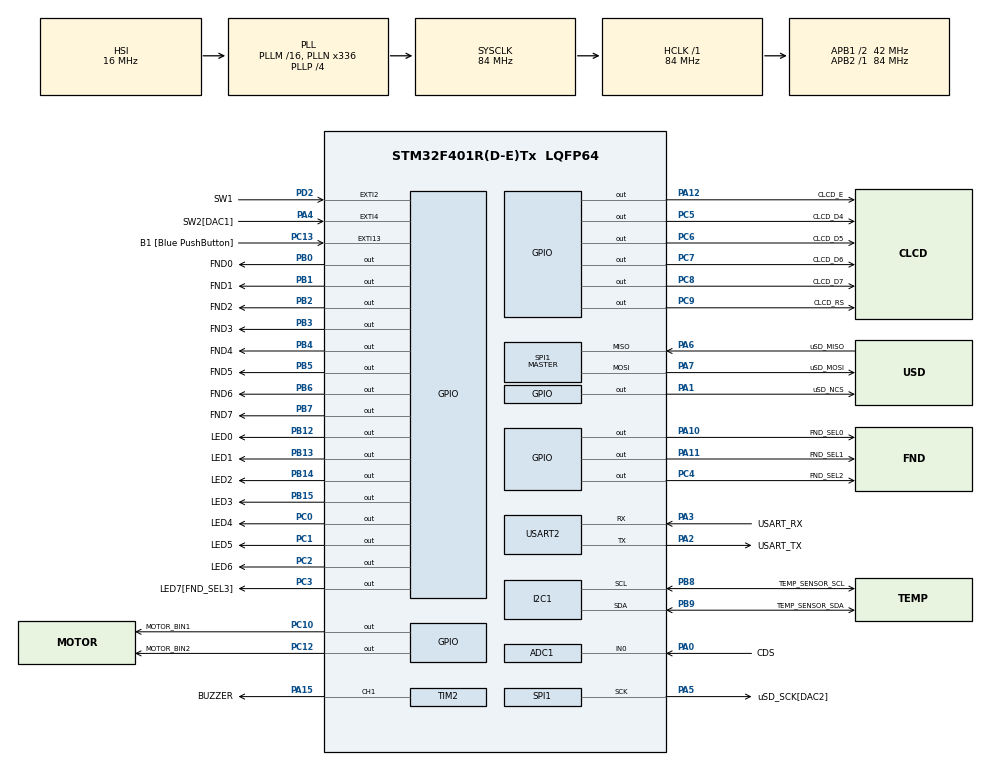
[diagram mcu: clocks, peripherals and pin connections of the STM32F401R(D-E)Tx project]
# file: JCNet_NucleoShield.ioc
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ADC1.Channel-0\#ChannelRegularConversion=ADC_CHANNEL_0
ADC1.Channel-1\#ChannelRegularConversion=ADC_CHANNEL_TEMPSENSOR
ADC1.ClockPrescaler=ADC_CLOCK_SYNC_PCLK_DIV4
ADC1.DMAContinuousRequests=ENABLE
ADC1.EOCSelection=ADC_EOC_SINGLE_CONV
ADC1.NbrOfConversion=2
ADC1.NbrOfConversionFlag=1
ADC1.Rank-0\#ChannelRegularConversion=1
ADC1.Rank-1\#ChannelRegularConversion=2
ADC1.SamplingTime-0\#ChannelRegularConversion=ADC_SAMPLETIME_480CYCLES
ADC1.SamplingTime-1\#ChannelRegularConversion=ADC_SAMPLETIME_480CYCLES
ADC1.ScanConvMode=ENABLE
ADC1.master=1
Dma.ADC1.0.Direction=DMA_PERIPH_TO_MEMORY
Dma.ADC1.0.FIFOMode=DMA_FIFOMODE_DISABLE
Dma.ADC1.0.Instance=DMA2_Stream0
Dma.ADC1.0.MemDataAlignment=DMA_MDATAALIGN_HALFWORD
Dma.ADC1.0.MemInc=DMA_MINC_ENABLE
Dma.ADC1.0.Mode=DMA_CIRCULAR
Dma.ADC1.0.PeriphDataAlignment=DMA_PDATAALIGN_HALFWORD
Dma.ADC1.0.PeriphInc=DMA_PINC_DISABLE
Dma.ADC1.0.Priority=DMA_PRIORITY_LOW
Dma.Request0=ADC1
Mcu.Family=STM32F4
Mcu.Name=STM32F401R(D-E)Tx
Mcu.Package=LQFP64
NVIC.ADC_IRQn=true\:0\:0\:false\:false\:true\:true\:true
NVIC.DMA2_Stream0_IRQn=true\:0\:0\:false\:false\:true\:false\:true
NVIC.EXTI2_IRQn=true\:0\:0\:true\:false\:true\:true\:true
NVIC.EXTI4_IRQn=true\:0\:0\:true\:false\:true\:true\:true
NVIC.PriorityGroup=NVIC_PRIORITYGROUP_4
NVIC.TIM2_IRQn=true\:0\:0\:false\:false\:true\:true\:true
PA0-WKUP.GPIO_Label=CDS
PA0-WKUP.Signal=ADCx_IN0
PA1.GPIO_Label=uSD_NCS
PA1.Signal=GPIO_Output
PA10.GPIO_Label=FND_SEL0
PA10.Signal=GPIO_Output
PA11.GPIO_Label=FND_SEL1
PA11.Signal=GPIO_Output
PA12.GPIO_Label=CLCD_E
PA12.GPIO_ModeDefaultOutputPP=GPIO_MODE_OUTPUT_OD
PA12.Signal=GPIO_Output
PA13.GPIO_Label=TMS
PA13.Mode=Serial_Wire
PA13.Signal=SYS_JTMS-SWDIO
PA14.GPIO_Label=TCK
PA14.Mode=Serial_Wire
PA14.Signal=SYS_JTCK-SWCLK
PA15.GPIO_Label=BUZZER
PA15.Signal=S_TIM2_CH1_ETR
PA2.GPIO_Label=USART_TX
PA2.GPIO_Mode=GPIO_MODE_AF_PP
PA2.GPIO_PuPd=GPIO_NOPULL
PA2.GPIO_Speed=GPIO_SPEED_FREQ_LOW
PA2.Mode=Asynchronous
PA2.Signal=USART2_TX
PA3.GPIO_Label=USART_RX
PA3.GPIO_Mode=GPIO_MODE_AF_PP
PA3.GPIO_PuPd=GPIO_NOPULL
PA3.GPIO_Speed=GPIO_SPEED_FREQ_LOW
PA3.Mode=Asynchronous
PA3.Signal=USART2_RX
PA4.GPIO_Label=SW2[DAC1]
PA4.GPIO_ModeDefaultEXTI=GPIO_MODE_IT_FALLING
PA4.Signal=GPXTI4
PA5.GPIO_Label=uSD_SCK[DAC2]
PA5.Mode=Full_Duplex_Master
PA5.Signal=SPI1_SCK
PA6.GPIO_Label=uSD_MISO
PA6.Mode=Full_Duplex_Master
PA6.Signal=SPI1_MISO
PA7.GPIO_Label=uSD_MOSI
PA7.Mode=Full_Duplex_Master
PA7.Signal=SPI1_MOSI
PA8.GPIO_Label=MOTOR_CH1
PA8.Signal=S_TIM1_CH1
PA9.GPIO_Label=MOTOR_CH2
PA9.Signal=S_TIM1_CH2
PB0.GPIO_Label=FND0
PB0.Signal=GPIO_Output
PB1.GPIO_Label=FND1
PB1.Signal=GPIO_Output
PB12.GPIO_Label=LED0
PB12.Signal=GPIO_Output
PB13.GPIO_Label=LED1
PB13.Signal=GPIO_Output
PB14.GPIO_Label=LED2
PB14.Signal=GPIO_Output
PB15.GPIO_Label=LED3
PB15.Signal=GPIO_Output
PB2.GPIO_Label=FND2
PB2.Signal=GPIO_Output
PB3.GPIO_Label=FND3
PB3.Signal=GPIO_Output
PB4.GPIO_Label=FND4
PB4.Signal=GPIO_Output
PB5.GPIO_Label=FND5
PB5.Signal=GPIO_Output
PB6.GPIO_Label=FND6
PB6.Signal=GPIO_Output
PB7.GPIO_Label=FND7
PB7.Signal=GPIO_Output
PB8.GPIO_Label=TEMP_SENSOR_SCL
PB8.Mode=I2C
PB8.Signal=I2C1_SCL
PB9.GPIO_Label=TEMP_SENSOR_SDA
PB9.Mode=I2C
PB9.Signal=I2C1_SDA
PC0.GPIO_Label=LED4
PC0.Signal=GPIO_Output
PC1.GPIO_Label=LED5
PC1.Signal=GPIO_Output
PC10.GPIO_Label=MOTOR_BIN1
PC10.Signal=GPIO_Output
PC12.GPIO_Label=MOTOR_BIN2
PC12.Signal=GPIO_Output
PC13-ANTI_TAMP.GPIO_Label=B1 [Blue PushButton]
PC13-ANTI_TAMP.GPIO_ModeDefaultEXTI=GPIO_MODE_IT_FALLING
PC13-ANTI_TAMP.GPIO_PuPd=GPIO_NOPULL
PC13-ANTI_TAMP.Signal=GPXTI13
PC14-OSC32_IN.Mode=LSE-External-Oscillator
PC14-OSC32_IN.Signal=RCC_OSC32_IN
PC15-OSC32_OUT.Mode=LSE-External-Oscillator
PC15-OSC32_OUT.Signal=RCC_OSC32_OUT
PC2.GPIO_Label=LED6
PC2.Signal=GPIO_Output
PC3.GPIO_Label=LED7[FND_SEL3]
PC3.Signal=GPIO_Output
PC4.GPIO_Label=FND_SEL2
PC4.Signal=GPIO_Output
PC5.GPIO_Label=CLCD_D4
PC5.GPIO_ModeDefaultOutputPP=GPIO_MODE_OUTPUT_OD
PC5.Signal=GPIO_Output
PC6.GPIO_Label=CLCD_D5
PC6.GPIO_ModeDefaultOutputPP=GPIO_MODE_OUTPUT_OD
PC6.Signal=GPIO_Output
PC7.GPIO_Label=CLCD_D6
PC7.GPIO_ModeDefaultOutputPP=GPIO_MODE_OUTPUT_OD
PC7.Signal=GPIO_Output
PC8.GPIO_Label=CLCD_D7
PC8.GPIO_ModeDefaultOutputPP=GPIO_MODE_OUTPUT_OD
PC8.Signal=GPIO_Output
PC9.GPIO_Label=CLCD_RS
PC9.GPIO_ModeDefaultOutputPP=GPIO_MODE_OUTPUT_OD
PC9.Signal=GPIO_Output
PD2.GPIO_Label=SW1
PD2.GPIO_ModeDefaultEXTI=GPIO_MODE_IT_FALLING
PD2.Signal=GPXTI2
PH0\ -\ OSC_IN.Mode=HSE-External-Clock-Source
PH0\ -\ OSC_IN.Signal=RCC_OSC_IN
PH1\ -\ OSC_OUT.Mode=HSE-External-Clock-Source
PH1\ -\ OSC_OUT.Signal=RCC_OSC_OUT
ProjectManager.HeapSize=0x200
ProjectManager.StackSize=0x400
ProjectManager.TargetToolchain=STM32CubeIDE
RCC.48MHZClocksFreq_Value=48000000
RCC.AHBFreq_Value=84000000
RCC.APB1CLKDivider=RCC_HCLK_DIV2
RCC.APB1Freq_Value=42000000
RCC.APB1TimFreq_Value=84000000
RCC.APB2Freq_Value=84000000
RCC.APB2TimFreq_Value=84000000
RCC.CortexFreq_Value=84000000
RCC.HCLKFreq_Value=84000000
RCC.HSE_VALUE=8000000
RCC.HSI_VALUE=16000000
RCC.PLLN=336
RCC.PLLP=RCC_PLLP_DIV4
RCC.PLLQ=7
RCC.SYSCLKFreq_VALUE=84000000
RCC.SYSCLKSource=RCC_SYSCLKSOURCE_PLLCLK
RCC.VCOOutputFreq_Value=336000000
SH.ADCx_IN0.0=ADC1_IN0,IN0
SH.S_TIM1_CH1.0=TIM1_CH1
SH.S_TIM1_CH2.0=TIM1_CH2
SH.S_TIM2_CH1_ETR.0=TIM2_CH1,PWM Generation1 CH1
SPI1.Direction=SPI_DIRECTION_2LINES
SPI1.Mode=SPI_MODE_MASTER
SPI1.VirtualType=VM_MASTER
TIM2.Channel-PWM\ Generation1\ CH1=TIM_CHANNEL_1
TIM2.Period=1000-1
TIM2.Prescaler=84-1
TIM2.Pulse-PWM\ Generation1\ CH1=500
USART2.VirtualMode=VM_ASYNC
VP_ADC1_TempSens_Input.Mode=IN-TempSens
board=NUCLEO-F401RE

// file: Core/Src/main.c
/* USER CODE BEGIN Header */
/**
  ******************************************************************************
  * @file           : main.c
  * @brief          : Main program body
  ******************************************************************************
  * @attention
  *
  * <h2><center>&copy; Copyright (c) 2020 STMicroelectronics.
  * All rights reserved.</center></h2>
  *
  * This software component is licensed by ST under BSD 3-Clause license,
  * the "License"; You may not use this file except in compliance with the
  * License. You may obtain a copy of the License at:
  *                        opensource.org/licenses/BSD-3-Clause
  *
  ******************************************************************************
  */
/* USER CODE END Header */

#include "main.h"

ADC_HandleTypeDef hadc1;
DMA_HandleTypeDef hdma_adc1;

I2C_HandleTypeDef hi2c1;

SPI_HandleTypeDef hspi1;

TIM_HandleTypeDef htim2;

UART_HandleTypeDef huart2;

void SystemClock_Config(void);
static void MX_GPIO_Init(void);
static void MX_DMA_Init(void);
static void MX_USART2_UART_Init(void);
static void MX_ADC1_Init(void);
static void MX_I2C1_Init(void);
static void MX_SPI1_Init(void);
static void MX_TIM2_Init(void);

int main(void)
{

  /* MCU Configuration--------------------------------------------------------*/

  /* Reset of all peripherals, Initializes the Flash interface and the Systick. */
  HAL_Init();

  /* Configure the system clock */
  SystemClock_Config();

  /* Initialize all configured peripherals */
  MX_GPIO_Init();
  MX_DMA_Init();
  MX_USART2_UART_Init();
  MX_ADC1_Init();
  MX_I2C1_Init();
  MX_SPI1_Init();
  MX_TIM2_Init();

  /* Infinite loop */
  /* USER CODE BEGIN WHILE */
  while (1)
  {
	  HAL_GPIO_TogglePin(LED0_GPIO_Port, LED0_Pin);
	  HAL_Delay(100);
    /* USER CODE END WHILE */

  }
}

void SystemClock_Config(void)
{
  RCC_OscInitTypeDef RCC_OscInitStruct = {0};
  RCC_ClkInitTypeDef RCC_ClkInitStruct = {0};

  /** Configure the main internal regulator output voltage
  */
  __HAL_RCC_PWR_CLK_ENABLE();
  __HAL_PWR_VOLTAGESCALING_CONFIG(PWR_REGULATOR_VOLTAGE_SCALE2);
  /** Initializes the CPU, AHB and APB busses clocks
  */
  RCC_OscInitStruct.OscillatorType = RCC_OSCILLATORTYPE_HSI;
  RCC_OscInitStruct.HSIState = RCC_HSI_ON;
  RCC_OscInitStruct.HSICalibrationValue = RCC_HSICALIBRATION_DEFAULT;
  RCC_OscInitStruct.PLL.PLLState = RCC_PLL_ON;
  RCC_OscInitStruct.PLL.PLLSource = RCC_PLLSOURCE_HSI;
  RCC_OscInitStruct.PLL.PLLM = 16;
  RCC_OscInitStruct.PLL.PLLN = 336;
  RCC_OscInitStruct.PLL.PLLP = RCC_PLLP_DIV4;
  RCC_OscInitStruct.PLL.PLLQ = 7;
  if (HAL_RCC_OscConfig(&RCC_OscInitStruct) != HAL_OK)
  {
    Error_Handler();
  }
  /** Initializes the CPU, AHB and APB busses clocks
  */
  RCC_ClkInitStruct.ClockType = RCC_CLOCKTYPE_HCLK|RCC_CLOCKTYPE_SYSCLK
                              |RCC_CLOCKTYPE_PCLK1|RCC_CLOCKTYPE_PCLK2;
  RCC_ClkInitStruct.SYSCLKSource = RCC_SYSCLKSOURCE_PLLCLK;
  RCC_ClkInitStruct.AHBCLKDivider = RCC_SYSCLK_DIV1;
  RCC_ClkInitStruct.APB1CLKDivider = RCC_HCLK_DIV2;
  RCC_ClkInitStruct.APB2CLKDivider = RCC_HCLK_DIV1;

  if (HAL_RCC_ClockConfig(&RCC_ClkInitStruct, FLASH_LATENCY_2) != HAL_OK)
  {
    Error_Handler();
  }
}

static void MX_ADC1_Init(void)
{

  ADC_ChannelConfTypeDef sConfig = {0};

  /** Configure the global features of the ADC (Clock, Resolution, Data Alignment and number of conversion)
  */
  hadc1.Instance = ADC1;
  hadc1.Init.ClockPrescaler = ADC_CLOCK_SYNC_PCLK_DIV4;
  hadc1.Init.Resolution = ADC_RESOLUTION_12B;
  hadc1.Init.ScanConvMode = ENABLE;
  hadc1.Init.ContinuousConvMode = DISABLE;
  hadc1.Init.DiscontinuousConvMode = DISABLE;
  hadc1.Init.ExternalTrigConvEdge = ADC_EXTERNALTRIGCONVEDGE_NONE;
  hadc1.Init.ExternalTrigConv = ADC_SOFTWARE_START;
  hadc1.Init.DataAlign = ADC_DATAALIGN_RIGHT;
  hadc1.Init.NbrOfConversion = 2;
  hadc1.Init.DMAContinuousRequests = ENABLE;
  hadc1.Init.EOCSelection = ADC_EOC_SINGLE_CONV;
  if (HAL_ADC_Init(&hadc1) != HAL_OK)
  {
    Error_Handler();
  }
  /** Configure for the selected ADC regular channel its corresponding rank in the sequencer and its sample time.
  */
  sConfig.Channel = ADC_CHANNEL_0;
  sConfig.Rank = 1;
  sConfig.SamplingTime = ADC_SAMPLETIME_480CYCLES;
  if (HAL_ADC_ConfigChannel(&hadc1, &sConfig) != HAL_OK)
  {
    Error_Handler();
  }
  /** Configure for the selected ADC regular channel its corresponding rank in the sequencer and its sample time.
  */
  sConfig.Channel = ADC_CHANNEL_TEMPSENSOR;
  sConfig.Rank = 2;
  if (HAL_ADC_ConfigChannel(&hadc1, &sConfig) != HAL_OK)
  {
    Error_Handler();
  }

}

static void MX_I2C1_Init(void)
{

  hi2c1.Instance = I2C1;
  hi2c1.Init.ClockSpeed = 100000;
  hi2c1.Init.DutyCycle = I2C_DUTYCYCLE_2;
  hi2c1.Init.OwnAddress1 = 0;
  hi2c1.Init.AddressingMode = I2C_ADDRESSINGMODE_7BIT;
  hi2c1.Init.DualAddressMode = I2C_DUALADDRESS_DISABLE;
  hi2c1.Init.OwnAddress2 = 0;
  hi2c1.Init.GeneralCallMode = I2C_GENERALCALL_DISABLE;
  hi2c1.Init.NoStretchMode = I2C_NOSTRETCH_DISABLE;
  if (HAL_I2C_Init(&hi2c1) != HAL_OK)
  {
    Error_Handler();
  }

}

static void MX_SPI1_Init(void)
{

  /* SPI1 parameter configuration*/
  hspi1.Instance = SPI1;
  hspi1.Init.Mode = SPI_MODE_MASTER;
  hspi1.Init.Direction = SPI_DIRECTION_2LINES;
  hspi1.Init.DataSize = SPI_DATASIZE_8BIT;
  hspi1.Init.CLKPolarity = SPI_POLARITY_LOW;
  hspi1.Init.CLKPhase = SPI_PHASE_1EDGE;
  hspi1.Init.NSS = SPI_NSS_SOFT;
  hspi1.Init.BaudRatePrescaler = SPI_BAUDRATEPRESCALER_2;
  hspi1.Init.FirstBit = SPI_FIRSTBIT_MSB;
  hspi1.Init.TIMode = SPI_TIMODE_DISABLE;
  hspi1.Init.CRCCalculation = SPI_CRCCALCULATION_DISABLE;
  hspi1.Init.CRCPolynomial = 10;
  if (HAL_SPI_Init(&hspi1) != HAL_OK)
  {
    Error_Handler();
  }

}

static void MX_TIM2_Init(void)
{

  TIM_MasterConfigTypeDef sMasterConfig = {0};
  TIM_OC_InitTypeDef sConfigOC = {0};

  htim2.Instance = TIM2;
  htim2.Init.Prescaler = 84-1;
  htim2.Init.CounterMode = TIM_COUNTERMODE_UP;
  htim2.Init.Period = 1000-1;
  htim2.Init.ClockDivision = TIM_CLOCKDIVISION_DIV1;
  htim2.Init.AutoReloadPreload = TIM_AUTORELOAD_PRELOAD_DISABLE;
  if (HAL_TIM_PWM_Init(&htim2) != HAL_OK)
  {
    Error_Handler();
  }
  sMasterConfig.MasterOutputTrigger = TIM_TRGO_RESET;
  sMasterConfig.MasterSlaveMode = TIM_MASTERSLAVEMODE_DISABLE;
  if (HAL_TIMEx_MasterConfigSynchronization(&htim2, &sMasterConfig) != HAL_OK)
  {
    Error_Handler();
  }
  sConfigOC.OCMode = TIM_OCMODE_PWM1;
  sConfigOC.Pulse = 500;
  sConfigOC.OCPolarity = TIM_OCPOLARITY_HIGH;
  sConfigOC.OCFastMode = TIM_OCFAST_DISABLE;
  if (HAL_TIM_PWM_ConfigChannel(&htim2, &sConfigOC, TIM_CHANNEL_1) != HAL_OK)
  {
    Error_Handler();
  }
  HAL_TIM_MspPostInit(&htim2);

}

static void MX_USART2_UART_Init(void)
{

  huart2.Instance = USART2;
  huart2.Init.BaudRate = 115200;
  huart2.Init.WordLength = UART_WORDLENGTH_8B;
  huart2.Init.StopBits = UART_STOPBITS_1;
  huart2.Init.Parity = UART_PARITY_NONE;
  huart2.Init.Mode = UART_MODE_TX_RX;
  huart2.Init.HwFlowCtl = UART_HWCONTROL_NONE;
  huart2.Init.OverSampling = UART_OVERSAMPLING_16;
  if (HAL_UART_Init(&huart2) != HAL_OK)
  {
    Error_Handler();
  }

}

static void MX_DMA_Init(void)
{

  /* DMA controller clock enable */
  __HAL_RCC_DMA2_CLK_ENABLE();

  /* DMA interrupt init */
  /* DMA2_Stream0_IRQn interrupt configuration */
  HAL_NVIC_SetPriority(DMA2_Stream0_IRQn, 0, 0);
  HAL_NVIC_EnableIRQ(DMA2_Stream0_IRQn);

}

static void MX_GPIO_Init(void)
{
  GPIO_InitTypeDef GPIO_InitStruct = {0};

  /* GPIO Ports Clock Enable */
  __HAL_RCC_GPIOC_CLK_ENABLE();
  __HAL_RCC_GPIOH_CLK_ENABLE();
  __HAL_RCC_GPIOA_CLK_ENABLE();
  __HAL_RCC_GPIOB_CLK_ENABLE();
  __HAL_RCC_GPIOD_CLK_ENABLE();

  /*Configure GPIO pin Output Level */
  HAL_GPIO_WritePin(GPIOC, LED4_Pin|LED5_Pin|LED6_Pin|LED7_Pin
                          |FND_SEL2_Pin|CLCD_D4_Pin|CLCD_D5_Pin|CLCD_D6_Pin
                          |CLCD_D7_Pin|CLCD_RS_Pin|MOTOR_BIN1_Pin|MOTOR_BIN2_Pin, GPIO_PIN_RESET);

  /*Configure GPIO pin Output Level */
  HAL_GPIO_WritePin(GPIOA, uSD_NCS_Pin|FND_SEL0_Pin|FND_SEL1_Pin|CLCD_E_Pin, GPIO_PIN_RESET);

  /*Configure GPIO pin Output Level */
  HAL_GPIO_WritePin(GPIOB, FND0_Pin|FND1_Pin|FND2_Pin|LED0_Pin
                          |LED1_Pin|LED2_Pin|LED3_Pin|FND3_Pin
                          |FND4_Pin|FND5_Pin|FND6_Pin|FND7_Pin, GPIO_PIN_RESET);

  /*Configure GPIO pin : B1_Pin */
  GPIO_InitStruct.Pin = B1_Pin;
  GPIO_InitStruct.Mode = GPIO_MODE_IT_FALLING;
  GPIO_InitStruct.Pull = GPIO_NOPULL;
  HAL_GPIO_Init(B1_GPIO_Port, &GPIO_InitStruct);

  /*Configure GPIO pins : LED4_Pin LED5_Pin LED6_Pin LED7_Pin
                           FND_SEL2_Pin MOTOR_BIN1_Pin MOTOR_BIN2_Pin */
  GPIO_InitStruct.Pin = LED4_Pin|LED5_Pin|LED6_Pin|LED7_Pin
                          |FND_SEL2_Pin|MOTOR_BIN1_Pin|MOTOR_BIN2_Pin;
  GPIO_InitStruct.Mode = GPIO_MODE_OUTPUT_PP;
  GPIO_InitStruct.Pull = GPIO_NOPULL;
  GPIO_InitStruct.Speed = GPIO_SPEED_FREQ_LOW;
  HAL_GPIO_Init(GPIOC, &GPIO_InitStruct);

  /*Configure GPIO pins : uSD_NCS_Pin FND_SEL0_Pin FND_SEL1_Pin */
  GPIO_InitStruct.Pin = uSD_NCS_Pin|FND_SEL0_Pin|FND_SEL1_Pin;
  GPIO_InitStruct.Mode = GPIO_MODE_OUTPUT_PP;
  GPIO_InitStruct.Pull = GPIO_NOPULL;
  GPIO_InitStruct.Speed = GPIO_SPEED_FREQ_LOW;
  HAL_GPIO_Init(GPIOA, &GPIO_InitStruct);

  /*Configure GPIO pin : SW2_Pin */
  GPIO_InitStruct.Pin = SW2_Pin;
  GPIO_InitStruct.Mode = GPIO_MODE_IT_FALLING;
  GPIO_InitStruct.Pull = GPIO_NOPULL;
  HAL_GPIO_Init(SW2_GPIO_Port, &GPIO_InitStruct);

  /*Configure GPIO pins : CLCD_D4_Pin CLCD_D5_Pin CLCD_D6_Pin CLCD_D7_Pin
                           CLCD_RS_Pin */
  GPIO_InitStruct.Pin = CLCD_D4_Pin|CLCD_D5_Pin|CLCD_D6_Pin|CLCD_D7_Pin
                          |CLCD_RS_Pin;
  GPIO_InitStruct.Mode = GPIO_MODE_OUTPUT_OD;
  GPIO_InitStruct.Pull = GPIO_NOPULL;
  GPIO_InitStruct.Speed = GPIO_SPEED_FREQ_LOW;
  HAL_GPIO_Init(GPIOC, &GPIO_InitStruct);

  /*Configure GPIO pins : FND0_Pin FND1_Pin FND2_Pin LED0_Pin
                           LED1_Pin LED2_Pin LED3_Pin FND3_Pin
                           FND4_Pin FND5_Pin FND6_Pin FND7_Pin */
  GPIO_InitStruct.Pin = FND0_Pin|FND1_Pin|FND2_Pin|LED0_Pin
                          |LED1_Pin|LED2_Pin|LED3_Pin|FND3_Pin
                          |FND4_Pin|FND5_Pin|FND6_Pin|FND7_Pin;
  GPIO_InitStruct.Mode = GPIO_MODE_OUTPUT_PP;
  GPIO_InitStruct.Pull = GPIO_NOPULL;
  GPIO_InitStruct.Speed = GPIO_SPEED_FREQ_LOW;
  HAL_GPIO_Init(GPIOB, &GPIO_InitStruct);

  /*Configure GPIO pins : MOTOR_CH1_Pin MOTOR_CH2_Pin */
  GPIO_InitStruct.Pin = MOTOR_CH1_Pin|MOTOR_CH2_Pin;
  GPIO_InitStruct.Mode = GPIO_MODE_AF_PP;
  GPIO_InitStruct.Pull = GPIO_NOPULL;
  GPIO_InitStruct.Speed = GPIO_SPEED_FREQ_LOW;
  GPIO_InitStruct.Alternate = GPIO_AF1_TIM1;
  HAL_GPIO_Init(GPIOA, &GPIO_InitStruct);

  /*Configure GPIO pin : CLCD_E_Pin */
  GPIO_InitStruct.Pin = CLCD_E_Pin;
  GPIO_InitStruct.Mode = GPIO_MODE_OUTPUT_OD;
  GPIO_InitStruct.Pull = GPIO_NOPULL;
  GPIO_InitStruct.Speed = GPIO_SPEED_FREQ_LOW;
  HAL_GPIO_Init(CLCD_E_GPIO_Port, &GPIO_InitStruct);

  /*Configure GPIO pin : SW1_Pin */
  GPIO_InitStruct.Pin = SW1_Pin;
  GPIO_InitStruct.Mode = GPIO_MODE_IT_FALLING;
  GPIO_InitStruct.Pull = GPIO_NOPULL;
  HAL_GPIO_Init(SW1_GPIO_Port, &GPIO_InitStruct);

  /* EXTI interrupt init*/
  HAL_NVIC_SetPriority(EXTI2_IRQn, 0, 0);
  HAL_NVIC_EnableIRQ(EXTI2_IRQn);

  HAL_NVIC_SetPriority(EXTI4_IRQn, 0, 0);
  HAL_NVIC_EnableIRQ(EXTI4_IRQn);

}

void Error_Handler(void)
{
}

/************************ (C) COPYRIGHT STMicroelectronics *****END OF FILE****/
